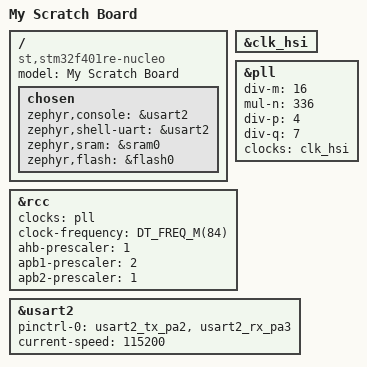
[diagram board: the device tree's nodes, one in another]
/dts-v1/;
#include <st/f4/stm32f401Xe.dtsi>
#include <st/f4/stm32f401r(d-e)tx-pinctrl.dtsi>

/ {
	model = "My Scratch Board";
	compatible = "st,stm32f401re-nucleo";

	chosen {
		zephyr,console = &usart2;
		zephyr,shell-uart = &usart2;
		zephyr,sram = &sram0;
		zephyr,flash = &flash0;
	};
};

&clk_hsi {
	status = "okay";
};

&pll {
	div-m = <16>;
	mul-n = <336>;
	div-p = <4>;
	div-q = <7>;
	clocks = <&clk_hsi>;
	status = "okay";
};

&rcc {
	clocks = <&pll>;
	clock-frequency = <DT_FREQ_M(84)>;
	ahb-prescaler = <1>;
	apb1-prescaler = <2>;
	apb2-prescaler = <1>;
};

&usart2 {
	pinctrl-0 = <&usart2_tx_pa2 &usart2_rx_pa3>;
	pinctrl-names = "default";
	current-speed = <115200>;
	status = "okay";
};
